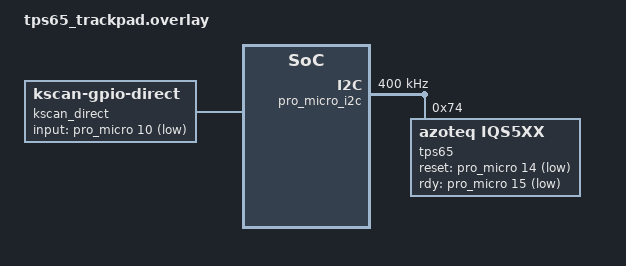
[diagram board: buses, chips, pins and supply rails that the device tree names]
#include <dt-bindings/zmk/matrix_transform.h>

/ {
    chosen {
        zmk,kscan = &kscan_direct;
        zmk,matrix-transform = &default_transform;
    };

    kscan_direct: kscan_direct {
        compatible = "zmk,kscan-gpio-direct";
        wakeup-source;

        input-gpios
            = <&pro_micro 10 (GPIO_ACTIVE_LOW | GPIO_PULL_UP)>;
    };

    default_transform: keymap_transform_0 {
        compatible = "zmk,matrix-transform";
        columns = <1>;
        rows = <1>;
        map = <RC(0,0)>;
    };

    tps65_input: tps65_input {
        compatible = "zmk,input-listener";
        device = <&tps65>;
    };
};

&pro_micro_i2c {
    status = "okay";
    clock-frequency = <400000>;
    tps65: iqs5xx@74 {
        status = "okay";
        compatible = "azoteq,iqs5xx";
        reg = <0x74>;

        reset-gpios = <&pro_micro 14 GPIO_ACTIVE_LOW>;
        rdy-gpios = <&pro_micro 15 GPIO_ACTIVE_LOW>;

        /*
         * Potentially non-exhaustive list of configuration options.
         * See: dts/bindings/input/azoteq,iqs5xx-common.yaml for a full list.
         */
        one-finger-tap;
        press-and-hold;
        press-and-hold-time = <180>;
        two-finger-tap;

        scroll;
        natural-scroll-x;

        bottom-beta = <15>;
        stationary-threshold = <5>;

        switch-xy;
    };
};

&tps65 {
    status = "okay";
};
